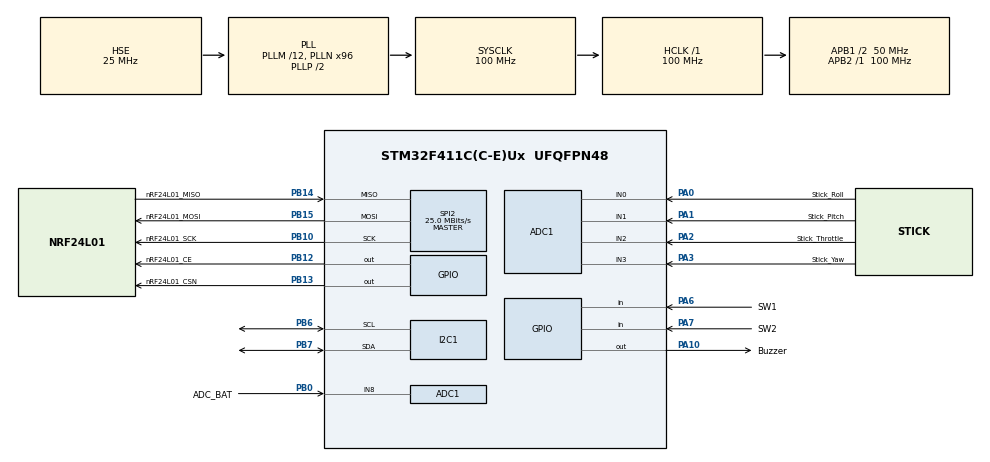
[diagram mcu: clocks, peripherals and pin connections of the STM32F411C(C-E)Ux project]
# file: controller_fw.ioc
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Mcu.Family=STM32F4
RCC.CortexFreq_Value=100000000
SPI2.VirtualType=VM_MASTER
PB10.Mode=Full_Duplex_Master
ADC1.ContinuousConvMode=ENABLE
SH.ADCx_IN2.0=ADC1_IN2,IN2
ADC1.SamplingTime-6\#ChannelRegularConversion=ADC_SAMPLETIME_84CYCLES
PB14.GPIO_Label=nRF24L01_MISO
PA6.GPIO_Label=SW1
PB0.GPIO_Label=ADC_BAT
PB13.GPIO_Label=nRF24L01_CSN
PB13.Signal=GPIO_Output
PB15.Signal=SPI2_MOSI
RCC.SYSCLKSource=RCC_SYSCLKSOURCE_PLLCLK
ProjectManager.StackSize=0x400
PH0\ -\ OSC_IN.Signal=RCC_OSC_IN
ADC1.Channel-5\#ChannelRegularConversion=ADC_CHANNEL_2
RCC.HCLKFreq_Value=100000000
SH.ADCx_IN3.0=ADC1_IN3,IN3
RCC.APB2TimFreq_Value=100000000
PB6.Signal=I2C1_SCL
Dma.ADC1.0.Direction=DMA_PERIPH_TO_MEMORY
PB6.Mode=I2C
NVIC.DMA2_Stream0_IRQn=true\:0\:0\:false\:false\:true\:false\:true
Dma.ADC1.0.MemDataAlignment=DMA_MDATAALIGN_WORD
RCC.AHBFreq_Value=100000000
ADC1.Channel-0\#ChannelRegularConversion=ADC_CHANNEL_0
RCC.HSE_VALUE=25000000
PB12.GPIO_Label=nRF24L01_CE
ADC1.SamplingTime-4\#ChannelRegularConversion=ADC_SAMPLETIME_84CYCLES
ADC1.Channel-6\#ChannelRegularConversion=ADC_CHANNEL_3
PC14-OSC32_IN.Mode=LSE-External-Oscillator
PA14.Mode=Serial_Wire
PB14.Mode=Full_Duplex_Master
Dma.ADC1.0.PeriphInc=DMA_PINC_DISABLE
PA10.GPIO_Label=Buzzer
SH.ADCx_IN8.0=ADC1_IN8,IN8
SPI2.CalculateBaudRate=25.0 MBits/s
PB7.Signal=I2C1_SDA
SH.ADCx_IN0.0=ADC1_IN0,IN0
ADC1.SamplingTime-0\#ChannelRegularConversion=ADC_SAMPLETIME_84CYCLES
Mcu.Package=UFQFPN48
PA6.Signal=GPIO_Input
SPI2.Mode=SPI_MODE_MASTER
PA2.GPIO_Label=Stick_Throttle
PA10.Signal=GPIO_Output
SH.ADCx_IN1.0=ADC1_IN1,IN1
RCC.APB1TimFreq_Value=100000000
Dma.ADC1.0.FIFOMode=DMA_FIFOMODE_DISABLE
SPI2.Direction=SPI_DIRECTION_2LINES
Dma.Request0=ADC1
ADC1.Rank-6\#ChannelRegularConversion=4
ADC1.EOCSelection=ADC_EOC_SINGLE_CONV
ADC1.Rank-4\#ChannelRegularConversion=2
PA3.Signal=ADCx_IN3
RCC.PLLSourceVirtual=RCC_PLLSOURCE_HSE
PC15-OSC32_OUT.Mode=LSE-External-Oscillator
Dma.ADC1.0.Instance=DMA2_Stream0
ADC1.Rank-0\#ChannelRegularConversion=1
ADC1.Channel-4\#ChannelRegularConversion=ADC_CHANNEL_1
PH1\ -\ OSC_OUT.Mode=HSE-External-Oscillator
RCC.APB1CLKDivider=RCC_HCLK_DIV2
PC14-OSC32_IN.Signal=RCC_OSC32_IN
PA0-WKUP.GPIO_Label=Stick_Roll
PA0-WKUP.Signal=ADCx_IN0
PA13.Signal=SYS_JTMS-SWDIO
Dma.ADC1.0.PeriphDataAlignment=DMA_PDATAALIGN_WORD
PH0\ -\ OSC_IN.Mode=HSE-External-Oscillator
ProjectManager.TargetToolchain=STM32CubeIDE
PB10.GPIO_Label=nRF24L01_SCK
Dma.ADC1.0.Mode=DMA_CIRCULAR
I2C1.I2C_Mode=I2C_Fast
Dma.ADC1.0.Priority=DMA_PRIORITY_MEDIUM
PC15-OSC32_OUT.Signal=RCC_OSC32_OUT
PA1.Signal=ADCx_IN1
PB10.Signal=SPI2_SCK
PB14.Signal=SPI2_MISO
PH1\ -\ OSC_OUT.Signal=RCC_OSC_OUT
board=custom
RCC.VCOOutputFreq_Value=200000000
PB15.Mode=Full_Duplex_Master
RCC.APB2Freq_Value=100000000
PB15.GPIO_Label=nRF24L01_MOSI
PA1.GPIO_Label=Stick_Pitch
ADC1.DMAContinuousRequests=ENABLE
ADC1.NbrOfConversion=4
PA13.Mode=Serial_Wire
Mcu.Name=STM32F411C(C-E)Ux
PA2.Signal=ADCx_IN2
RCC.48MHZClocksFreq_Value=50000000
RCC.SYSCLKFreq_VALUE=100000000
PA7.GPIO_Label=SW2
ADC1.master=1
PB7.Mode=I2C
PA14.Signal=SYS_JTCK-SWCLK
Dma.ADC1.0.MemInc=DMA_MINC_ENABLE
ProjectManager.HeapSize=0x200
ADC1.SamplingTime-5\#ChannelRegularConversion=ADC_SAMPLETIME_84CYCLES
RCC.HSI_VALUE=16000000
NVIC.PriorityGroup=NVIC_PRIORITYGROUP_4
ADC1.NbrOfConversionFlag=1
RCC.PLLM=12
RCC.PLLN=96
RCC.APB1Freq_Value=50000000
PB0.Signal=ADCx_IN8
ADC1.ClockPrescaler=ADC_CLOCK_SYNC_PCLK_DIV4
ADC1.Rank-5\#ChannelRegularConversion=3
PB12.Signal=GPIO_Output
PA3.GPIO_Label=Stick_Yaw
PA7.Signal=GPIO_Input

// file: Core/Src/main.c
/* USER CODE BEGIN Header */
/**
  ******************************************************************************
  * @file           : main.c
  * @brief          : Main program body
  ******************************************************************************
  * @attention
  *
  * <h2><center>&copy; Copyright (c) 2021 STMicroelectronics.
  * All rights reserved.</center></h2>
  *
  * This software component is licensed by ST under BSD 3-Clause license,
  * the "License"; You may not use this file except in compliance with the
  * License. You may obtain a copy of the License at:
  *                        opensource.org/licenses/BSD-3-Clause
  *
  ******************************************************************************
  */
/* USER CODE END Header */
#include "main.h"
#include "adc.h"
#include "dma.h"
#include "i2c.h"
#include "spi.h"
#include "gpio.h"

/* USER CODE BEGIN Includes */

#include "display.h"

/* USER CODE END Includes */

void SystemClock_Config(void);

int main(void)
{

  /* MCU Configuration--------------------------------------------------------*/

  /* Reset of all peripherals, Initializes the Flash interface and the Systick. */
  HAL_Init();

  /* Configure the system clock */
  SystemClock_Config();

  /* Initialize all configured peripherals */
  MX_GPIO_Init();
  MX_DMA_Init();
  MX_ADC1_Init();
  MX_I2C1_Init();
  MX_SPI2_Init();
  /* USER CODE BEGIN 2 */

  joystick_init();
  ssd1306_init();

  /* USER CODE END 2 */

  /* Infinite loop */
  while (1)
  {

    /* USER CODE BEGIN 3 */
	  display_joystick_value();
	  HAL_Delay(10);

  }
  /* USER CODE END 3 */
}

void SystemClock_Config(void)
{
  RCC_OscInitTypeDef RCC_OscInitStruct = {0};
  RCC_ClkInitTypeDef RCC_ClkInitStruct = {0};

  /** Configure the main internal regulator output voltage
  */
  __HAL_RCC_PWR_CLK_ENABLE();
  __HAL_PWR_VOLTAGESCALING_CONFIG(PWR_REGULATOR_VOLTAGE_SCALE1);
  /** Initializes the RCC Oscillators according to the specified parameters
  * in the RCC_OscInitTypeDef structure.
  */
  RCC_OscInitStruct.OscillatorType = RCC_OSCILLATORTYPE_HSE;
  RCC_OscInitStruct.HSEState = RCC_HSE_ON;
  RCC_OscInitStruct.PLL.PLLState = RCC_PLL_ON;
  RCC_OscInitStruct.PLL.PLLSource = RCC_PLLSOURCE_HSE;
  RCC_OscInitStruct.PLL.PLLM = 12;
  RCC_OscInitStruct.PLL.PLLN = 96;
  RCC_OscInitStruct.PLL.PLLP = RCC_PLLP_DIV2;
  RCC_OscInitStruct.PLL.PLLQ = 4;
  if (HAL_RCC_OscConfig(&RCC_OscInitStruct) != HAL_OK)
  {
    Error_Handler();
  }
  /** Initializes the CPU, AHB and APB buses clocks
  */
  RCC_ClkInitStruct.ClockType = RCC_CLOCKTYPE_HCLK|RCC_CLOCKTYPE_SYSCLK
                              |RCC_CLOCKTYPE_PCLK1|RCC_CLOCKTYPE_PCLK2;
  RCC_ClkInitStruct.SYSCLKSource = RCC_SYSCLKSOURCE_PLLCLK;
  RCC_ClkInitStruct.AHBCLKDivider = RCC_SYSCLK_DIV1;
  RCC_ClkInitStruct.APB1CLKDivider = RCC_HCLK_DIV2;
  RCC_ClkInitStruct.APB2CLKDivider = RCC_HCLK_DIV1;

  if (HAL_RCC_ClockConfig(&RCC_ClkInitStruct, FLASH_LATENCY_3) != HAL_OK)
  {
    Error_Handler();
  }
}

void Error_Handler(void)
{
  __disable_irq();
  while (1)
  {
  }
}

/************************ (C) COPYRIGHT STMicroelectronics *****END OF FILE****/
